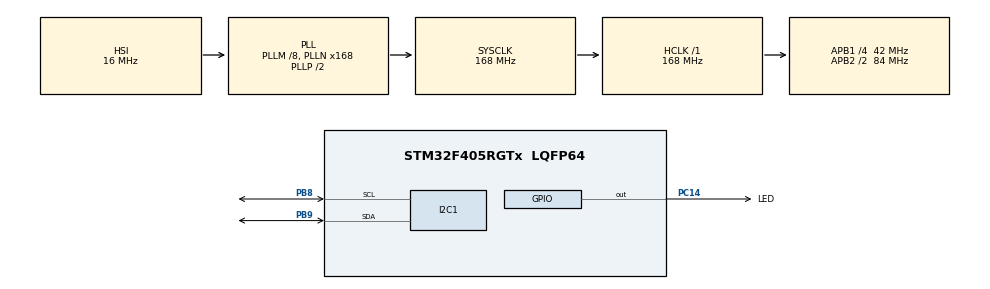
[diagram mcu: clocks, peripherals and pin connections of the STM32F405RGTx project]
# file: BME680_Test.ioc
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I2C1.I2C_Mode=I2C_Fast
Mcu.Family=STM32F4
Mcu.Name=STM32F405RGTx
Mcu.Package=LQFP64
NVIC.PriorityGroup=NVIC_PRIORITYGROUP_4
PA13.Mode=Serial_Wire
PA13.Signal=SYS_JTMS-SWDIO
PA14.Mode=Serial_Wire
PA14.Signal=SYS_JTCK-SWCLK
PB8.Mode=I2C
PB8.Signal=I2C1_SCL
PB9.Mode=I2C
PB9.Signal=I2C1_SDA
PC14-OSC32_IN.GPIO_Label=LED
PC14-OSC32_IN.Signal=GPIO_Output
ProjectManager.HeapSize=0x200
ProjectManager.StackSize=0x400
ProjectManager.TargetToolchain=STM32CubeIDE
RCC.48MHZClocksFreq_Value=84000000
RCC.AHBFreq_Value=168000000
RCC.APB1CLKDivider=RCC_HCLK_DIV4
RCC.APB1Freq_Value=42000000
RCC.APB1TimFreq_Value=84000000
RCC.APB2CLKDivider=RCC_HCLK_DIV2
RCC.APB2Freq_Value=84000000
RCC.APB2TimFreq_Value=168000000
RCC.CortexFreq_Value=168000000
RCC.HCLKFreq_Value=168000000
RCC.HSE_VALUE=25000000
RCC.HSI_VALUE=16000000
RCC.LSE_VALUE=32768
RCC.PLLM=8
RCC.PLLN=168
RCC.SYSCLKFreq_VALUE=168000000
RCC.SYSCLKSource=RCC_SYSCLKSOURCE_PLLCLK
RCC.VCOOutputFreq_Value=336000000
board=custom

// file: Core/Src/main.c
/* USER CODE BEGIN Header */
/**
  ******************************************************************************
  * @file           : main.c
  * @brief          : Main program body
  ******************************************************************************
  * @attention
  *
  * Copyright (c) 2025 STMicroelectronics.
  * All rights reserved.
  *
  * This software is licensed under terms that can be found in the LICENSE file
  * in the root directory of this software component.
  * If no LICENSE file comes with this software, it is provided AS-IS.
  *
  ******************************************************************************
  */
/* USER CODE END Header */
#include "main.h"
#include "i2c.h"
#include "gpio.h"

/* USER CODE BEGIN Includes */
//#include "bme_active_object.h"
//#include "bme_callback.h"
#include "bme680.h"
#include "sig_sensors.h"
/* USER CODE END Includes */

/* USER CODE BEGIN PD */
//static bme_proobject_t bmeA0s;
/* USER CODE END PD */

/* USER CODE BEGIN PM */
//static void bme_proobject_event_dispatcher(bme_proobject_t *const mobj,bme_event_t const *const e);
/* USER CODE END PM */

void SystemClock_Config(void);
/* USER CODE BEGIN PFP */
void fnAPP_Init_Standard_Values();
/* USER CODE END PFP */

/* USER CODE BEGIN 0 */
static st_bme680_t bme;
/* USER CODE END 0 */

int main(void)
{

  /* MCU Configuration--------------------------------------------------------*/

  /* Reset of all peripherals, Initializes the Flash interface and the Systick. */
  HAL_Init();

  /* Configure the system clock */
  SystemClock_Config();

  /* Initialize all configured peripherals */
  MX_GPIO_Init();
  MX_I2C1_Init();
  /* USER CODE BEGIN 2 */
//  bme_proobject_init(&bmeA0s);
  fnAPP_Init_Standard_Values();
  init_bme680(&bme);
  struct bme680_field_data data;
  /* USER CODE END 2 */

  /* Infinite loop */
  while (1)
  {

    /* USER CODE BEGIN 3 */
//	uint8_t proevent;
//	bme_proobject_user_event_t ue;
//	proevent = get_bme_internal_signal();
//	bme_proobject_user_event_t te;
//	te.super.sig = BME_TICK_SIG;
//	bme_proobject_event_dispatcher(&bmeA0s,&te.super);
//
//	if(proevent == BME_GET_DATA_DEFINE){
//		reset_bme_internal_signal();
//		ue.super.sig = READ_BME_SENSOR_SIG;
//		bme_proobject_event_dispatcher(&bmeA0s,&ue.super);
//	}
//	else if(proevent ==BME_HEATING_SENSORS_DEFINE){
//		reset_bme_internal_signal();
//		ue.super.sig = BME_HEATING_SIG;
//		bme_proobject_event_dispatcher(&bmeA0s,&ue.super);
//	}
//	HAL_Delay(10);
	  bme680_get_sensor_data(&data, &bme.gas_sensor);
	  		bme.temperature = data.temperature / 100.0f;
	  		bme.pressure = data.pressure / 100.0f;
	  		bme.humidity = data.humidity / 1000.0f;

	  		if(data.status & BME680_GASM_VALID_MSK)
	  				bme.gas_resistance = data.gas_resistance;

//	  		printf("T:%lu; t:%.2f; p:%.0f; h:%.0f, ",
//	  				HAL_GetTick(), bme.temperature, bme.pressure, bme.humidity);

	  		if ((bme.getgasreference_count++) % 5 == 0)
	  			bme_GetGasReference(&bme);

	  		bme_calculateIAQ( bme_GetHumidityScore(&bme) + bme_GetGasScore(&bme) );

	  		/* USER CODE END WHILE */

	  		/* USER CODE BEGIN 3 */
	  		user_delay_ms(2000); /* Delay till the measurement is ready - bme.meas_period */

	  		/* Trigger the next measurement if you would like to read data out continuously */
	  		if (bme.gas_sensor.power_mode == BME680_FORCED_MODE) {
	  			bme680_set_sensor_mode(&bme.gas_sensor);
	  		}
  }

  /* USER CODE END 3 */
}

void SystemClock_Config(void)
{
  RCC_OscInitTypeDef RCC_OscInitStruct = {0};
  RCC_ClkInitTypeDef RCC_ClkInitStruct = {0};

  /** Configure the main internal regulator output voltage
  */
  __HAL_RCC_PWR_CLK_ENABLE();
  __HAL_PWR_VOLTAGESCALING_CONFIG(PWR_REGULATOR_VOLTAGE_SCALE1);

  /** Initializes the RCC Oscillators according to the specified parameters
  * in the RCC_OscInitTypeDef structure.
  */
  RCC_OscInitStruct.OscillatorType = RCC_OSCILLATORTYPE_HSI;
  RCC_OscInitStruct.HSIState = RCC_HSI_ON;
  RCC_OscInitStruct.HSICalibrationValue = RCC_HSICALIBRATION_DEFAULT;
  RCC_OscInitStruct.PLL.PLLState = RCC_PLL_ON;
  RCC_OscInitStruct.PLL.PLLSource = RCC_PLLSOURCE_HSI;
  RCC_OscInitStruct.PLL.PLLM = 8;
  RCC_OscInitStruct.PLL.PLLN = 168;
  RCC_OscInitStruct.PLL.PLLP = RCC_PLLP_DIV2;
  RCC_OscInitStruct.PLL.PLLQ = 4;
  if (HAL_RCC_OscConfig(&RCC_OscInitStruct) != HAL_OK)
  {
    Error_Handler();
  }

  /** Initializes the CPU, AHB and APB buses clocks
  */
  RCC_ClkInitStruct.ClockType = RCC_CLOCKTYPE_HCLK|RCC_CLOCKTYPE_SYSCLK
                              |RCC_CLOCKTYPE_PCLK1|RCC_CLOCKTYPE_PCLK2;
  RCC_ClkInitStruct.SYSCLKSource = RCC_SYSCLKSOURCE_PLLCLK;
  RCC_ClkInitStruct.AHBCLKDivider = RCC_SYSCLK_DIV1;
  RCC_ClkInitStruct.APB1CLKDivider = RCC_HCLK_DIV4;
  RCC_ClkInitStruct.APB2CLKDivider = RCC_HCLK_DIV2;

  if (HAL_RCC_ClockConfig(&RCC_ClkInitStruct, FLASH_LATENCY_5) != HAL_OK)
  {
    Error_Handler();
  }
}

/* USER CODE BEGIN 4 */
//static void bme_proobject_event_dispatcher(bme_proobject_t *const mobj,bme_event_t const *const e){
//
//  bme_event_status_t status;
//  bme_proobject_state_t source, target;
//
//  source = mobj->active_state;
//  status = bme_proobject_state_machine(mobj,e);
//
//  if(status == BME_EVENT_TRANSITION){
//    target = mobj->active_state;
//    bme_event_t ee;
//    //1. run the exit action for the source state
//    ee.sig = BME_EXIT;
//    mobj->active_state = source;
//    bme_proobject_state_machine(mobj,&ee);
//
//    //2. run the entry action for the target state
//    ee.sig = BME_ENTRY;
//    mobj->active_state = target;
//    bme_proobject_state_machine(mobj,&ee);
//  }
//}
void fnAPP_Init_Standard_Values(void){

	bme.gas_weighting = 0.75;
	bme.gas_reference = 2500;
	bme.getgasreference_count = 0;
	bme.hum_weighting = 0.25;
	bme.hum_reference = 40;
	bme.gas_lower_limit = 10000;
	bme.gas_upper_limit = 300000;

}
/* USER CODE END 4 */

void Error_Handler(void)
{
  __disable_irq();
  while (1)
  {
  }
}
